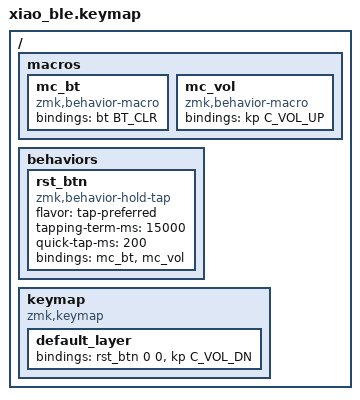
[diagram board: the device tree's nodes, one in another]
/* FINAL_DUMMY_ARG_v8 */
#include <behaviors.dtsi>
#include <dt-bindings/zmk/keys.h>
#include <dt-bindings/zmk/bt.h>

/ {
    /* 1. 裏方：実際の動きをマクロで作っておく */
    macros {
        /* BT消去マクロ */
        mc_bt: mc_bt {
            compatible = "zmk,behavior-macro";
            #binding-cells = <0>;
            bindings = <&bt BT_CLR>;
        };
        /* 音量UPマクロ */
        mc_vol: mc_vol {
            compatible = "zmk,behavior-macro";
            #binding-cells = <0>;
            bindings = <&kp C_VOL_UP>;
        };
    };

    behaviors {
        /* 2. ボタン定義：引数は2つ取るが、無視してマクロを呼ぶ */
        rst_btn: rst_btn {
            compatible = "zmk,behavior-hold-tap";
            #binding-cells = <2>; /* ルール通り2にする！ */
            flavor = "tap-preferred";
            tapping-term-ms = <15000>;
            quick-tap-ms = <200>;
            /* 引数が来ても無視して、固定のマクロを発動させる */
            bindings = <&mc_bt>, <&mc_vol>;
        };
    };

    keymap {
        compatible = "zmk,keymap";

        default_layer {
            bindings = <
                /* ボタン1：ダミーの「0 0」を渡す（これでエラー回避！） */
                &rst_btn 0 0
                
                /* ボタン2：ダミーの音量ダウン */
                &kp C_VOL_DN
            >;
        };
    };
};
